# ESP32-C6 register map
Vendor: ESPRESSIF SYSTEMS (SHANGHAI) CO., LTD.; Series: ESP32 C-Series; File version: 12
CPU: RV32IMAC r0p0, little endian, no MPU, no FPU, 0 interrupt priority bits
Address unit: 32 bits
Registers are 32-bit, read-write, reset 0x0 unless marked. A register's access mark holds for its fields unless they carry their own. Offsets are from the block's base; [hi:lo] are bit positions; {n}, {i} and the like mark numbered series.

## ATOMIC — Atomic Locker
Base 0x60011000
0x00 ADDR_LOCK — hardware lock regsiter
  [1:0] LOCK — read to acquire hardware lock, write to release hardware lock
0x04 LR_ADDR — gloable lr address regsiter
  [31:0] GLOABLE_LR_ADDR — backup gloable address
0x08 LR_VALUE — gloable lr value regsiter
  [31:0] GLOABLE_LR_VALUE — backup gloable value
0x0C LOCK_STATUS ro — lock status regsiter
  [1:0] LOCK_STATUS — read hareware lock status for debug
0x10 COUNTER — wait counter register
  [15:0] WAIT_COUNTER — delay counter

## DS — Digital Signature
Base 0x6008C000
{0x0+4i} Y_MEM[{i}] (i=0..127) access not given — memory that stores Y
{0x200+4i} M_MEM[{i}] (i=0..127) access not given — memory that stores M
{0x400+4i} RB_MEM[{i}] (i=0..127) access not given — memory that stores Rb
{0x600+4i} BOX_MEM[{i}] (i=0..11) access not given — memory that stores BOX
{0x630+4i} IV_MEM[{i}] (i=0..3) access not given — memory that stores IV
{0x800+4i} X_MEM[{i}] (i=0..127) access not given — memory that stores X
{0xA00+4i} Z_MEM[{i}] (i=0..127) access not given — memory that stores Z
0xE00 SET_START wo — DS start control register
  [0] SET_START — set this bit to start DS operation.
0xE04 SET_CONTINUE wo — DS continue control register
  [0] SET_CONTINUE — set this bit to continue DS operation.
0xE08 SET_FINISH wo — DS finish control register
  [0] SET_FINISH — Set this bit to finish DS process.
0xE0C QUERY_BUSY ro — DS query busy register
  [0] QUERY_BUSY — digital signature state. 1'b0: idle, 1'b1: busy
0xE10 QUERY_KEY_WRONG ro — DS query key-wrong counter register
  [3:0] QUERY_KEY_WRONG — digital signature key wrong counter
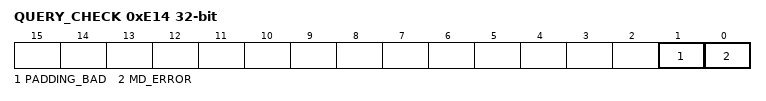
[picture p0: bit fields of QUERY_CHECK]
0xE14 QUERY_CHECK ro — DS query check result register
  [1] PADDING_BAD — padding checkout result. 1'b0: a good padding, 1'b1: a bad padding
  [0] MD_ERROR — MD checkout result. 1'b0: MD check pass, 1'b1: MD check fail
0xE20 DATE — DS version control register

## ECC — ECC (ECC Hardware Accelerator)
Base 0x6008B000
0x0C MULT_INT_RAW ro — ECC interrupt raw register, valid in level.
  [0] CALC_DONE — The raw interrupt status bit for the ecc_calc_done_int interrupt
0x10 MULT_INT_ST ro — ECC interrupt status register.
  [0] CALC_DONE — The masked interrupt status bit for the ecc_calc_done_int interrupt
0x14 MULT_INT_ENA — ECC interrupt enable register.
  [0] CALC_DONE — The interrupt enable bit for the ecc_calc_done_int interrupt
0x18 MULT_INT_CLR wo — ECC interrupt clear register.
  [0] CALC_DONE write-1-clears — Set this bit to clear the ecc_calc_done_int interrupt
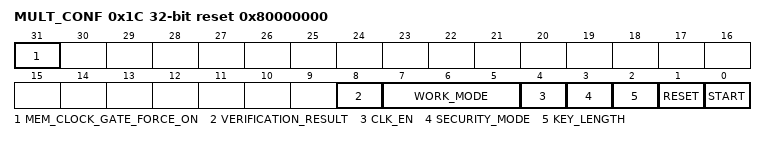
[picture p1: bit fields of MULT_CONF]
0x1C MULT_CONF access per field reset 0x80000000 — ECC configure register
  [31] MEM_CLOCK_GATE_FORCE_ON rw — ECC memory clock gate force on register
  [8] VERIFICATION_RESULT ro — The verification result bit of ECC Accelerator, only valid when calculation is done.
  [7:5] WORK_MODE rw — The work mode bits of ECC Accelerator. 0: Point Mult Mode. 1: Division mode. 2: Point verification mode. 3: Point Verif+mult mode. 4: Jacobian Point Mult Mode. 5: Reserved. 6: Jacobian Point Verification Mode. 7: Point Verif + Jacobian Mult Mode.
  [4] CLK_EN rw — Write 1 to force on register clock gate.
  [3] SECURITY_MODE rw — Reserved
  [2] KEY_LENGTH rw — The key length mode bit of ECC Accelerator. 0: P-192. 1: P-256.
    0=P192 (P-192 elliptic curve); 1=P256 (P-256 elliptic curve)
  [1] RESET wo — Write 1 to reset ECC Accelerator.
  [0] START rw — Write 1 to start caculation of ECC Accelerator. This bit will be self-cleared after the caculatrion is done.
0xFC MULT_DATE — Version control register
{0x100+4i} K_MEM[{i}] (i=0..7) access not given — The memory that stores k.
{0x120+4i} PX_MEM[{i}] (i=0..7) access not given — The memory that stores Px.
{0x140+4i} PY_MEM[{i}] (i=0..7) access not given — The memory that stores Py.
